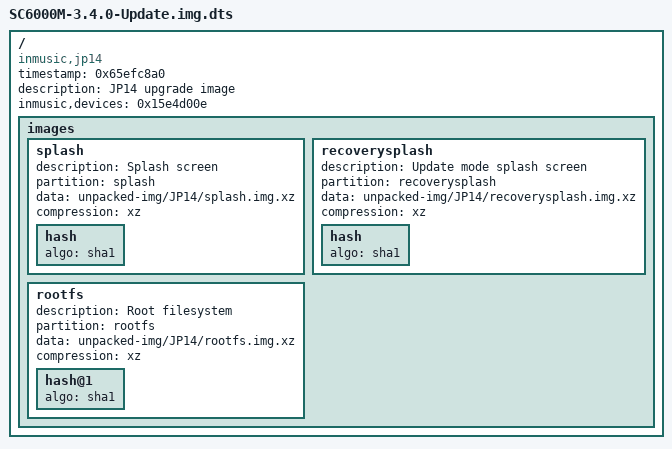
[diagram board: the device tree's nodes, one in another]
/dts-v1/;

/ {
	timestamp = <0x65efc8a0>;
	description = "JP14 upgrade image";
	compatible = "inmusic,jp14";
	inmusic,devices = <0x15e4d00e>;

	images {

		splash {
			description = "Splash screen";
			partition = "splash";
			data = /incbin/("unpacked-img/JP14/splash.img.xz");
			compression = "xz";

			hash {
				algo = "sha1";
			};
		};

		recoverysplash {
			description = "Update mode splash screen";
			partition = "recoverysplash";
			data = /incbin/("unpacked-img/JP14/recoverysplash.img.xz");
			compression = "xz";

			hash {
				algo = "sha1";
			};
		};

		rootfs {
			description = "Root filesystem";
			partition = "rootfs";
			data = /incbin/("unpacked-img/JP14/rootfs.img.xz");
			compression = "xz";

			hash@1 {
				algo = "sha1";
			};
		};
	};
};
